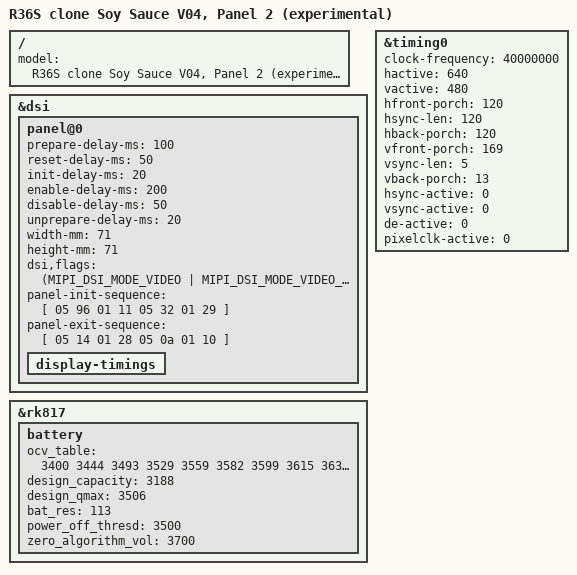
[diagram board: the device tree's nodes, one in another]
// SPDX-License-Identifier: (GPL-2.0+ OR MIT)
/*
 * EXPERIMENTAL - not tested on hardware by andr36oid. Keep a copy of the
 * files you replace so you can go back.
 *
 * Soy Sauce Y3506_V04_20250529 2548 "Panel 2" (two-command init sequence).
 * Sources: dArkOSRE port by southoz (dArkOSRE-R36, soysauce/... 2548 Panel 2),
 * K4uanGP's "soy sauce v04" andr36oid port (Andr36oid-dtb-for-Clones).
 */

/dts-v1/;
#include "rk3326-r36s-clone-soysauce.dtsi"

/ {
	model = "R36S clone Soy Sauce V04, Panel 2 (experimental)";
};

&dsi {
	panel@0 {
		prepare-delay-ms = <100>;
		reset-delay-ms = <50>;
		init-delay-ms = <20>;
		enable-delay-ms = <200>;
		disable-delay-ms = <50>;
		unprepare-delay-ms = <20>;
		width-mm = <71>;
		height-mm = <71>;
		dsi,flags = <(MIPI_DSI_MODE_VIDEO |
		      MIPI_DSI_MODE_VIDEO_BURST |
		      MIPI_DSI_MODE_EOT_PACKET |
		      MIPI_DSI_MODE_LPM)>;
		panel-init-sequence = [
			05 96 01 11
			05 32 01 29
		];
		panel-exit-sequence = [
			05 14 01 28
			05 0a 01 10
		];
		display-timings {
			/* one mode only: the R36S alternates below do not fit this panel */
			/delete-node/ timing1;
			/delete-node/ timing2;
		};
	};
};

&timing0 {
	clock-frequency = <40000000>;
	hactive = <640>;
	vactive = <480>;
	hfront-porch = <120>;
	hsync-len = <120>;
	hback-porch = <120>;
	vfront-porch = <169>;	/* was 17: 77.7 Hz; 59.97 Hz, same pixel clock */
	vsync-len = <5>;
	vback-porch = <13>;
	hsync-active = <0>;
	vsync-active = <0>;
	de-active = <0>;
	pixelclk-active = <0>;
};

&rk817 {
	battery {
		/*
		 * Stock values of the V04 2548 Panel 2 batch (its U-Boot DTB;
		 * K4uanGP's V04 kernel DTBs and southoz's dArkOSRE port agree).
		 */
		ocv_table = <3400 3444 3493 3529 3559 3582 3599
			3615 3634 3660 3701 3759 3809 3852
			3886 3911 3961 4012 4028 4075 4182>;
		design_capacity = <3188>;
		design_qmax = <3506>;
		bat_res = <113>;
		power_off_thresd = <3500>;
		zero_algorithm_vol = <3700>;
	};
};
